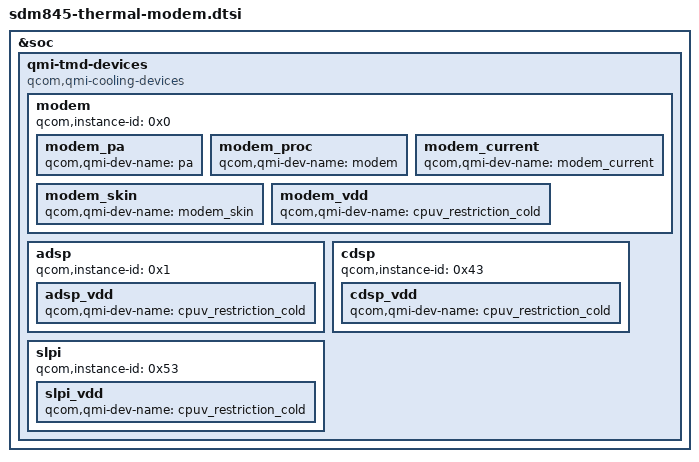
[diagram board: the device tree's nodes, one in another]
// SPDX-License-Identifier: GPL-2.0-only
/*
 * Copyright (c) 2025, Pavel Dubrova <pashadubrova@gmail.com>
 */

#include <dt-bindings/thermal/thermal.h>

&soc {
	qmi-tmd-devices {
		compatible = "qcom,qmi-cooling-devices";

		modem {
			qcom,instance-id = <0x0>;

			modem_pa: modem_pa {
				qcom,qmi-dev-name = "pa";
				#cooling-cells = <2>;
			};

			modem_proc: modem_proc {
				qcom,qmi-dev-name = "modem";
				#cooling-cells = <2>;
			};

			modem_current: modem_current {
				qcom,qmi-dev-name = "modem_current";
				#cooling-cells = <2>;
			};

			modem_skin: modem_skin {
				qcom,qmi-dev-name = "modem_skin";
				#cooling-cells = <2>;
			};

			modem_vdd: modem_vdd {
				qcom,qmi-dev-name = "cpuv_restriction_cold";
				#cooling-cells = <2>;
			};
		};

		adsp {
			qcom,instance-id = <0x1>;

			adsp_vdd: adsp_vdd {
				qcom,qmi-dev-name = "cpuv_restriction_cold";
				#cooling-cells = <2>;
			};
		};

		cdsp {
			qcom,instance-id = <0x43>;

			cdsp_vdd: cdsp_vdd {
				qcom,qmi-dev-name = "cpuv_restriction_cold";
				#cooling-cells = <2>;
			};
		};

		slpi {
			qcom,instance-id = <0x53>;

			slpi_vdd: slpi_vdd {
				qcom,qmi-dev-name = "cpuv_restriction_cold";
				#cooling-cells = <2>;
			};
		};
	};
};
